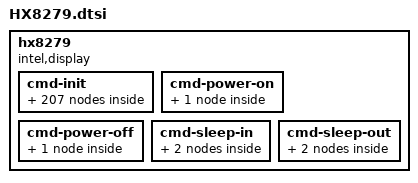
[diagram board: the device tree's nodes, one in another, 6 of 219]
	hx8279 {
		compatible = "intel,display";
		intel,display-resolution= <600 1024>;
		intel,display-dpi= <169 169>;

		/* MIPI-DSI video mode settings */
		intel,display-vid-hfp-hs-bytes = <60>;
		intel,display-vid-hbp-hs-bytes = <108>;
		intel,display-vid-hsa-hs-bytes = <72>;
		intel,display-vid-vfp-lines = <6>;
		intel,display-vid-vbp-lines = <8>;
		intel,display-vid-vsa-lines = <2>;

		intel,display-vid-mode = "pulses";
		intel,display-vid-id = <0>;
		intel,display-vid-pixel = "24packed";
		intel,display-vid-fill_buf_to = <0x1F>;

		intel,display-reset = <1 1 0 2 1 10>;

		cmd-init {
			soft-reset {
				intel,cmd-type = <0x05>;
				intel,cmd-data = <0x01>;
				intel,cmd-delay = <20>;
				intel,cmd-lp = <1>;
			};
			change-paga-number-0 {
				intel,cmd-type = <0x15>;
				intel,cmd-data = <0xB0 0x00>;
				intel,cmd-lp = <1>;
			};
			source-line {
				intel,cmd-type = <0x15>;
				intel,cmd-data = <0xBA 0xA4>;
				intel,cmd-lp = <1>;
			};
			set-vcom {
				intel,cmd-type = <0x15>;
				intel,cmd-data = <0xBD 0x71>;
				intel,cmd-lp = <1>;
			};
			set-vdd {
				intel,cmd-type = <0x15>;
				intel,cmd-data = <0xBE 0x22>;
				intel,cmd-lp = <1>;
			};
			set-vgh {
				intel,cmd-type = <0x15>;
				intel,cmd-data = <0xBF 0x19>;
				intel,cmd-lp = <1>;
			};
			set-vgl {
				intel,cmd-type = <0x15>;
				intel,cmd-data = <0xC0 0x10>;
				intel,cmd-lp = <1>;
			};
			set-pfm {
				intel,cmd-type = <0x15>;
				intel,cmd-data = <0xC1 0x78>;
				intel,cmd-lp = <1>;
			};
			set-drvp {
				intel,cmd-type = <0x15>;
				intel,cmd-data = <0xC2 0x2C>;
				intel,cmd-lp = <1>;
			};
			set-drvn {
				intel,cmd-type = <0x15>;
				intel,cmd-data = <0xC3 0x82>;
				intel,cmd-lp = <1>;
			};
			set-charge-pump {
				intel,cmd-type = <0x15>;
				intel,cmd-data = <0xC4 0x73>;
				intel,cmd-lp = <1>;
			};
			set-vgph {
				intel,cmd-type = <0x15>;
				intel,cmd-data = <0xC5 0x05>;
				intel,cmd-lp = <1>;
			};
			set-vgpl {
				intel,cmd-type = <0x15>;
				intel,cmd-data = <0xC6 0x02>;
				intel,cmd-lp = <1>;
			};
			set-vgnh {
				intel,cmd-type = <0x15>;
				intel,cmd-data = <0xC7 0x05>;
				intel,cmd-lp = <1>;
			};
			set-vgnl {
				intel,cmd-type = <0x15>;
				intel,cmd-data = <0xC8 0x03>;
				intel,cmd-lp = <1>;
			};
			set-eq0 {
				intel,cmd-type = <0x15>;
				intel,cmd-data = <0xC9 0x18>;
				intel,cmd-lp = <1>;
			};
			set-page-number-1 {
				intel,cmd-type = <0x15>;
				intel,cmd-data = <0xB0 0x01>;
				intel,cmd-lp = <1>;
			};
			pgamma-0 {
				intel,cmd-type = <0x15>;
				intel,cmd-data = <0xB1 0x00>;
				intel,cmd-lp = <1>;
			};
			pgamma-1 {
				intel,cmd-type = <0x15>;
				intel,cmd-data = <0xB2 0x2C>;
				intel,cmd-lp = <1>;
			};
			pgamma-2 {
				intel,cmd-type = <0x15>;
				intel,cmd-data = <0xB3 0x5C>;
				intel,cmd-lp = <1>;
			};
			pgamma-3 {
				intel,cmd-type = <0x15>;
				intel,cmd-data = <0xB4 0xAC>;
				intel,cmd-lp = <1>;
			};
			pgamma-4 {
				intel,cmd-type = <0x15>;
				intel,cmd-data = <0xB5 0xDC>;
				intel,cmd-lp = <1>;
			};
			pgamma-5 {
				intel,cmd-type = <0x15>;
				intel,cmd-data = <0xB6 0x5C>;
				intel,cmd-lp = <1>;
			};
			pgamma-6 {
				intel,cmd-type = <0x15>;
				intel,cmd-data = <0xB7 0x9C>;
				intel,cmd-lp = <1>;
			};
			pgamma-7 {
				intel,cmd-type = <0x15>;
				intel,cmd-data = <0xB8 0xCC>;
				intel,cmd-lp = <1>;
			};
			pgamma-8 {
				intel,cmd-type = <0x15>;
				intel,cmd-data = <0xB9 0x0C>;
				intel,cmd-lp = <1>;
			};
			pgamma-9 {
				intel,cmd-type = <0x15>;
				intel,cmd-data = <0xBA 0x3C>;
				intel,cmd-lp = <1>;
			};
			pgamma-10 {
				intel,cmd-type = <0x15>;
				intel,cmd-data = <0xBB 0x6C>;
				intel,cmd-lp = <1>;
			};
			pgamma-11 {
				intel,cmd-type = <0x15>;
				intel,cmd-data = <0xBC 0x9C>;
				intel,cmd-lp = <1>;
			};
			pgamma-12 {
				intel,cmd-type = <0x15>;
				intel,cmd-data = <0xBD 0xCC>;
				intel,cmd-lp = <1>;
			};
			pgamma-13 {
				intel,cmd-type = <0x15>;
				intel,cmd-data = <0xBE 0xFC>;
				intel,cmd-lp = <1>;
			};
			pgamma-14 {
				intel,cmd-type = <0x15>;
				intel,cmd-data = <0xBF 0x2C>;
				intel,cmd-lp = <1>;
			};
			pgamma-15 {
				intel,cmd-type = <0x15>;
				intel,cmd-data = <0xC0 0x5C>;
				intel,cmd-lp = <1>;
			};
			pgamma-16 {
				intel,cmd-type = <0x15>;
				intel,cmd-data = <0xC1 0xFC>;
				intel,cmd-lp = <1>;
			};
			pgamma-17 {
				intel,cmd-type = <0x15>;
				intel,cmd-data = <0xC2 0x00>;
				intel,cmd-lp = <1>;
			};
			pgamma-18 {
				intel,cmd-type = <0x15>;
				intel,cmd-data = <0xC3 0x15>;
				intel,cmd-lp = <1>;
			};
			pgamma-19 {
				intel,cmd-type = <0x15>;
				intel,cmd-data = <0xC4 0xAA>;
				intel,cmd-lp = <1>;
			};
			pgamma-20 {
				intel,cmd-type = <0x15>;
				intel,cmd-data = <0xC5 0xAF>;
				intel,cmd-lp = <1>;
			};
			pgamma-21 {
				intel,cmd-type = <0x15>;
				intel,cmd-data = <0xC6 0x03>;
				intel,cmd-lp = <1>;
			};
			pgamma-22 {
				intel,cmd-type = <0x15>;
				intel,cmd-data = <0xC7 0x00>;
				intel,cmd-lp = <1>;
			};
			pgamma-23 {
				intel,cmd-type = <0x15>;
				intel,cmd-data = <0xC8 0x2C>;
				intel,cmd-lp = <1>;
			};
			pgamma-24 {
				intel,cmd-type = <0x15>;
				intel,cmd-data = <0xC9 0x5C>;
				intel,cmd-lp = <1>;
			};
			pgamma-25 {
				intel,cmd-type = <0x15>;
				intel,cmd-data = <0xCA 0xAC>;
				intel,cmd-lp = <1>;
			};
			pgamma-26 {
				intel,cmd-type = <0x15>;
				intel,cmd-data = <0xCB 0xDC>;
				intel,cmd-lp = <1>;
			};
			pgamma-27 {
				intel,cmd-type = <0x15>;
				intel,cmd-data = <0xCC 0x5C>;
				intel,cmd-lp = <1>;
			};
			pgamma-28 {
				intel,cmd-type = <0x15>;
				intel,cmd-data = <0xCD 0x9C>;
				intel,cmd-lp = <1>;
			};
			pgamma-29 {
				intel,cmd-type = <0x15>;
				intel,cmd-data = <0xCE 0xCC>;
				intel,cmd-lp = <1>;
			};
			pgamma-30 {
				intel,cmd-type = <0x15>;
				intel,cmd-data = <0xCF 0x0C>;
				intel,cmd-lp = <1>;
			};
			pgamma-31 {
				intel,cmd-type = <0x15>;
				intel,cmd-data = <0xD0 0x3C>;
				intel,cmd-lp = <1>;
			};
			pgamma-32 {
				intel,cmd-type = <0x15>;
				intel,cmd-data = <0xD1 0x6C>;
				intel,cmd-lp = <1>;
			};
			pgamma-33 {
				intel,cmd-type = <0x15>;
				intel,cmd-data = <0xD2 0x9C>;
				intel,cmd-lp = <1>;
			};
			pgamma-34 {
				intel,cmd-type = <0x15>;
				intel,cmd-data = <0xD3 0xCC>;
				intel,cmd-lp = <1>;
			};
			pgamma-35 {
				intel,cmd-type = <0x15>;
				intel,cmd-data = <0xD4 0xFC>;
				intel,cmd-lp = <1>;
			};
			pgamma-36 {
				intel,cmd-type = <0x15>;
				intel,cmd-data = <0xD5 0x2C>;
				intel,cmd-lp = <1>;
			};
			pgamma-37 {
				intel,cmd-type = <0x15>;
				intel,cmd-data = <0xD6 0x5C>;
				intel,cmd-lp = <1>;
			};
			pgamma-38 {
				intel,cmd-type = <0x15>;
				intel,cmd-data = <0xD7 0xFC>;
				intel,cmd-lp = <1>;
			};
			pgamma-39 {
				intel,cmd-type = <0x15>;
				intel,cmd-data = <0xD8 0x00>;
				intel,cmd-lp = <1>;
			};
			pgamma-40 {
				intel,cmd-type = <0x15>;
				intel,cmd-data = <0xD9 0x15>;
				intel,cmd-lp = <1>;
			};
			pgamma-41 {
				intel,cmd-type = <0x15>;
				intel,cmd-data = <0xDA 0xAA>;
				intel,cmd-lp = <1>;
			};
			pgamma-42 {
				intel,cmd-type = <0x15>;
				intel,cmd-data = <0xDB 0xAF>;
				intel,cmd-lp = <1>;
			};
			pgamma-43 {
				intel,cmd-type = <0x15>;
				intel,cmd-data = <0xDC 0x03>;
				intel,cmd-lp = <1>;
			};
			pgamma-44 {
				intel,cmd-type = <0x15>;
				intel,cmd-data = <0xDD 0x00>;
				intel,cmd-lp = <1>;
			};
			pgamma-45 {
				intel,cmd-type = <0x15>;
				intel,cmd-data = <0xDE 0x2C>;
				intel,cmd-lp = <1>;
			};
			pgamma-46 {
				intel,cmd-type = <0x15>;
				intel,cmd-data = <0xDF 0x5C>;
				intel,cmd-lp = <1>;
			};
			pgamma-47 {
				intel,cmd-type = <0x15>;
				intel,cmd-data = <0xE0 0xAC>;
				intel,cmd-lp = <1>;
			};
			pgamma-48 {
				intel,cmd-type = <0x15>;
				intel,cmd-data = <0xE1 0xDC>;
				intel,cmd-lp = <1>;
			};
			pgamma-49 {
				intel,cmd-type = <0x15>;
				intel,cmd-data = <0xE2 0x5C>;
				intel,cmd-lp = <1>;
			};
			pgamma-50 {
				intel,cmd-type = <0x15>;
				intel,cmd-data = <0xE3 0x9C>;
				intel,cmd-lp = <1>;
			};
			pgamma-51 {
				intel,cmd-type = <0x15>;
				intel,cmd-data = <0xE4 0xCC>;
				intel,cmd-lp = <1>;
			};
			pgamma-52 {
				intel,cmd-type = <0x15>;
				intel,cmd-data = <0xE5 0x0C>;
				intel,cmd-lp = <1>;
			};
			pgamma-53 {
				intel,cmd-type = <0x15>;
				intel,cmd-data = <0xE6 0x3C>;
				intel,cmd-lp = <1>;
			};
			pgamma-54 {
				intel,cmd-type = <0x15>;
				intel,cmd-data = <0xE7 0x6C>;
				intel,cmd-lp = <1>;
			};
			pgamma-55 {
				intel,cmd-type = <0x15>;
				intel,cmd-data = <0xE8 0x9C>;
				intel,cmd-lp = <1>;
			};
			pgamma-56 {
				intel,cmd-type = <0x15>;
				intel,cmd-data = <0xE9 0xCC>;
				intel,cmd-lp = <1>;
			};
			pgamma-57 {
				intel,cmd-type = <0x15>;
				intel,cmd-data = <0xEA 0xFC>;
				intel,cmd-lp = <1>;
			};
			pgamma-58 {
				intel,cmd-type = <0x15>;
				intel,cmd-data = <0xEB 0x2C>;
				intel,cmd-lp = <1>;
			};
			pgamma-59 {
				intel,cmd-type = <0x15>;
				intel,cmd-data = <0xEC 0x5C>;
				intel,cmd-lp = <1>;
			};
			pgamma-60 {
				intel,cmd-type = <0x15>;
				intel,cmd-data = <0xED 0xFC>;
				intel,cmd-lp = <1>;
			};
			pgamma-61 {
				intel,cmd-type = <0x15>;
				intel,cmd-data = <0xEE 0x00>;
				intel,cmd-lp = <1>;
			};
			pgamma-62 {
				intel,cmd-type = <0x15>;
				intel,cmd-data = <0xEF 0x15>;
				intel,cmd-lp = <1>;
			};
			pgamma-63 {
				intel,cmd-type = <0x15>;
				intel,cmd-data = <0xF0 0xAA>;
				intel,cmd-lp = <1>;
			};
			pgamma-64 {
				intel,cmd-type = <0x15>;
				intel,cmd-data = <0xF1 0xAF>;
				intel,cmd-lp = <1>;
			};
			pgamma-65 {
				intel,cmd-type = <0x15>;
				intel,cmd-data = <0xF2 0x03>;
				intel,cmd-lp = <1>;
			};
			set-page-number-2 {
				intel,cmd-type = <0x15>;
				intel,cmd-data = <0xB0 0x02>;
				intel,cmd-lp = <1>;
			};
			ngamma-0 {
				intel,cmd-type = <0x15>;
				intel,cmd-data = <0xB1 0x00>;
				intel,cmd-lp = <1>;
			};
			ngamma-1 {
				intel,cmd-type = <0x15>;
				intel,cmd-data = <0xB2 0x2C>;
				intel,cmd-lp = <1>;
			};
			ngamma-2 {
				intel,cmd-type = <0x15>;
				intel,cmd-data = <0xB3 0x5C>;
				intel,cmd-lp = <1>;
			};
			ngamma-3 {
				intel,cmd-type = <0x15>;
				intel,cmd-data = <0xB4 0xAC>;
				intel,cmd-lp = <1>;
			};
			ngamma-4 {
				intel,cmd-type = <0x15>;
				intel,cmd-data = <0xB5 0xDC>;
				intel,cmd-lp = <1>;
			};
			ngamma-5 {
				intel,cmd-type = <0x15>;
				intel,cmd-data = <0xB6 0x5C>;
				intel,cmd-lp = <1>;
			};
			ngamma-6 {
				intel,cmd-type = <0x15>;
				intel,cmd-data = <0xB7 0x9C>;
				intel,cmd-lp = <1>;
			};
			ngamma-7 {
				intel,cmd-type = <0x15>;
				intel,cmd-data = <0xB8 0xCC>;
				intel,cmd-lp = <1>;
			};
			ngamma-8 {
				intel,cmd-type = <0x15>;
				intel,cmd-data = <0xB9 0x0C>;
				intel,cmd-lp = <1>;
			};
			ngamma-9 {
				intel,cmd-type = <0x15>;
				intel,cmd-data = <0xBA 0x3C>;
				intel,cmd-lp = <1>;
			};
			ngamma-10 {
				intel,cmd-type = <0x15>;
				intel,cmd-data = <0xBB 0x6C>;
				intel,cmd-lp = <1>;
			};
			ngamma-11 {
				intel,cmd-type = <0x15>;
				intel,cmd-data = <0xBC 0x9C>;
				intel,cmd-lp = <1>;
			};
			ngamma-12 {
				intel,cmd-type = <0x15>;
				intel,cmd-data = <0xBD 0xCC>;
				intel,cmd-lp = <1>;
			};
			ngamma-13 {
				intel,cmd-type = <0x15>;
				intel,cmd-data = <0xBE 0xFC>;
				intel,cmd-lp = <1>;
			};
			ngamma-14 {
				intel,cmd-type = <0x15>;
				intel,cmd-data = <0xBF 0x2C>;
				intel,cmd-lp = <1>;
			};
			ngamma-15 {
				intel,cmd-type = <0x15>;
				intel,cmd-data = <0xC0 0x5C>;
				intel,cmd-lp = <1>;
			};
			ngamma-16 {
				intel,cmd-type = <0x15>;
				intel,cmd-data = <0xC1 0xFC>;
				intel,cmd-lp = <1>;
			};
			ngamma-17 {
				intel,cmd-type = <0x15>;
				intel,cmd-data = <0xC2 0x00>;
				intel,cmd-lp = <1>;
			};
			ngamma-18 {
				intel,cmd-type = <0x15>;
				intel,cmd-data = <0xC3 0x15>;
				intel,cmd-lp = <1>;
			};
			ngamma-19 {
				intel,cmd-type = <0x15>;
				intel,cmd-data = <0xC4 0xAA>;
				intel,cmd-lp = <1>;
			};
			ngamma-20 {
				intel,cmd-type = <0x15>;
				intel,cmd-data = <0xC5 0xAF>;
				intel,cmd-lp = <1>;
			};
			ngamma-21 {
				intel,cmd-type = <0x15>;
				intel,cmd-data = <0xC6 0x03>;
				intel,cmd-lp = <1>;
			};
			ngamma-22 {
				intel,cmd-type = <0x15>;
				intel,cmd-data = <0xC7 0x00>;
				intel,cmd-lp = <1>;
			};
			ngamma-23 {
				intel,cmd-type = <0x15>;
				intel,cmd-data = <0xC8 0x2C>;
				intel,cmd-lp = <1>;
			};
			ngamma-24 {
				intel,cmd-type = <0x15>;
				intel,cmd-data = <0xC9 0x5C>;
				intel,cmd-lp = <1>;
			};
			ngamma-25 {
				intel,cmd-type = <0x15>;
				intel,cmd-data = <0xCA 0xAC>;
				intel,cmd-lp = <1>;
			};
			ngamma-26 {
				intel,cmd-type = <0x15>;
				intel,cmd-data = <0xCB 0xDC>;
				intel,cmd-lp = <1>;
			};
			ngamma-27 {
				intel,cmd-type = <0x15>;
				intel,cmd-data = <0xCC 0x5C>;
				intel,cmd-lp = <1>;
			};
			ngamma-28 {
				intel,cmd-type = <0x15>;
				intel,cmd-data = <0xCD 0x9C>;
				intel,cmd-lp = <1>;
			};
			ngamma-29 {
				intel,cmd-type = <0x15>;
				intel,cmd-data = <0xCE 0xCC>;
				intel,cmd-lp = <1>;
			};
			ngamma-30 {
				intel,cmd-type = <0x15>;
				intel,cmd-data = <0xCF 0x0C>;
				intel,cmd-lp = <1>;
			};
			ngamma-31 {
				intel,cmd-type = <0x15>;
				intel,cmd-data = <0xD0 0x3C>;
				intel,cmd-lp = <1>;
			};
			ngamma-32 {
				intel,cmd-type = <0x15>;
				intel,cmd-data = <0xD1 0x6C>;
				intel,cmd-lp = <1>;
			};
			ngamma-33 {
				intel,cmd-type = <0x15>;
				intel,cmd-data = <0xD2 0x9C>;
				intel,cmd-lp = <1>;
			};
			ngamma-34 {
				intel,cmd-type = <0x15>;
				intel,cmd-data = <0xD3 0xCC>;
				intel,cmd-lp = <1>;
			};
			ngamma-35 {
				intel,cmd-type = <0x15>;
				intel,cmd-data = <0xD4 0xFC>;
				intel,cmd-lp = <1>;
			};
			ngamma-36 {
				intel,cmd-type = <0x15>;
				intel,cmd-data = <0xD5 0x2C>;
				intel,cmd-lp = <1>;
			};
			ngamma-37 {
				intel,cmd-type = <0x15>;
				intel,cmd-data = <0xD6 0x5C>;
				intel,cmd-lp = <1>;
			};
			ngamma-38 {
				intel,cmd-type = <0x15>;
				intel,cmd-data = <0xD7 0xFC>;
				intel,cmd-lp = <1>;
			};
			ngamma-39 {
				intel,cmd-type = <0x15>;
				intel,cmd-data = <0xD8 0x00>;
				intel,cmd-lp = <1>;
			};
			ngamma-40 {
				intel,cmd-type = <0x15>;
				intel,cmd-data = <0xD9 0x15>;
				intel,cmd-lp = <1>;
			};
			ngamma-41 {
				intel,cmd-type = <0x15>;
				intel,cmd-data = <0xDA 0xAA>;
				intel,cmd-lp = <1>;
			};
			ngamma-42 {
				intel,cmd-type = <0x15>;
				intel,cmd-data = <0xDB 0xAF>;
				intel,cmd-lp = <1>;
			};
			ngamma-43 {
				intel,cmd-type = <0x15>;
				intel,cmd-data = <0xDC 0x03>;
				intel,cmd-lp = <1>;
			};
			ngamma-44 {
				intel,cmd-type = <0x15>;
				intel,cmd-data = <0xDD 0x00>;
				intel,cmd-lp = <1>;
			};
			ngamma-45 {
				intel,cmd-type = <0x15>;
				intel,cmd-data = <0xDE 0x2C>;
				intel,cmd-lp = <1>;
			};
			ngamma-46 {
				intel,cmd-type = <0x15>;
				intel,cmd-data = <0xDF 0x5C>;
				intel,cmd-lp = <1>;
			};
			ngamma-47 {
				intel,cmd-type = <0x15>;
				intel,cmd-data = <0xE0 0xAC>;
				intel,cmd-lp = <1>;
			};
			ngamma-48 {
				intel,cmd-type = <0x15>;
				intel,cmd-data = <0xE1 0xDC>;
				intel,cmd-lp = <1>;
			};
			ngamma-49 {
				intel,cmd-type = <0x15>;
				intel,cmd-data = <0xE2 0x5C>;
				intel,cmd-lp = <1>;
			};
			ngamma-50 {
				intel,cmd-type = <0x15>;
				intel,cmd-data = <0xE3 0x9C>;
				intel,cmd-lp = <1>;
			};
			ngamma-51 {
				intel,cmd-type = <0x15>;
				intel,cmd-data = <0xE4 0xCC>;
				intel,cmd-lp = <1>;
			};
			ngamma-52 {
				intel,cmd-type = <0x15>;
				intel,cmd-data = <0xE5 0x0C>;
				intel,cmd-lp = <1>;
			};
			ngamma-53 {
				intel,cmd-type = <0x15>;
				intel,cmd-data = <0xE6 0x3C>;
				intel,cmd-lp = <1>;
			};
			ngamma-54 {
				intel,cmd-type = <0x15>;
				intel,cmd-data = <0xE7 0x6C>;
				intel,cmd-lp = <1>;
			};
			ngamma-55 {
				intel,cmd-type = <0x15>;
				intel,cmd-data = <0xE8 0x9C>;
				intel,cmd-lp = <1>;
			};
			ngamma-56 {
				intel,cmd-type = <0x15>;
				intel,cmd-data = <0xE9 0xCC>;
				intel,cmd-lp = <1>;
			};
			ngamma-57 {
				intel,cmd-type = <0x15>;
				intel,cmd-data = <0xEA 0xFC>;
				intel,cmd-lp = <1>;
			};
			ngamma-58 {
				intel,cmd-type = <0x15>;
				intel,cmd-data = <0xEB 0x2C>;
				intel,cmd-lp = <1>;
			};
			ngamma-59 {
				intel,cmd-type = <0x15>;
				intel,cmd-data = <0xEC 0x5C>;
				intel,cmd-lp = <1>;
			};
			ngamma-60 {
				intel,cmd-type = <0x15>;
				intel,cmd-data = <0xED 0xFC>;
				intel,cmd-lp = <1>;
			};
			ngamma-61 {
				intel,cmd-type = <0x15>;
				intel,cmd-data = <0xEE 0x00>;
				intel,cmd-lp = <1>;
			};
			ngamma-62 {
				intel,cmd-type = <0x15>;
				intel,cmd-data = <0xEF 0x15>;
				intel,cmd-lp = <1>;
			};
			ngamma-63 {
				intel,cmd-type = <0x15>;
				intel,cmd-data = <0xF0 0xAA>;
				intel,cmd-lp = <1>;
			};
			ngamma-64 {
				intel,cmd-type = <0x15>;
				intel,cmd-data = <0xF1 0xAF>;
				intel,cmd-lp = <1>;
			};
			ngamma-65 {
				intel,cmd-type = <0x15>;
				intel,cmd-data = <0xF2 0x03>;
				intel,cmd-lp = <1>;
			};
			set-page-number-3 {
				intel,cmd-type = <0x15>;
				intel,cmd-data = <0xB0 0x03>;
				intel,cmd-lp = <1>;
			};
			set-goa-0 {
				intel,cmd-type = <0x15>;
				intel,cmd-data = <0xC0 0x40>;
				intel,cmd-lp = <1>;
			};
			set-goa-1 {
				intel,cmd-type = <0x15>;
				intel,cmd-data = <0xC1 0x10>;
				intel,cmd-lp = <1>;
			};
			set-goa-2 {
				intel,cmd-type = <0x15>;
				intel,cmd-data = <0xC4 0x2F>;
				intel,cmd-lp = <1>;
			};
			set-goa-3 {
				intel,cmd-type = <0x15>;
				intel,cmd-data = <0xC5 0x9E>;
				intel,cmd-lp = <1>;
			};
			set-goa-4 {
				intel,cmd-type = <0x15>;
				intel,cmd-data = <0xC8 0x41>;
				intel,cmd-lp = <1>;
			};
			set-goa-5 {
				intel,cmd-type = <0x15>;
				intel,cmd-data = <0xC9 0x61>;
				intel,cmd-lp = <1>;
			};
			set-goa-6 {
				intel,cmd-type = <0x15>;
				intel,cmd-data = <0xCA 0x01>;
				intel,cmd-lp = <1>;
			};
			set-goa-7 {
				intel,cmd-type = <0x15>;
				intel,cmd-data = <0xCB 0x00>;
				intel,cmd-lp = <1>;
			};
			set-gout-0 {
				intel,cmd-type = <0x15>;
				intel,cmd-data = <0xDC 0x01>;
				intel,cmd-lp = <1>;
			};
			set-gout-1 {
				intel,cmd-type = <0x15>;
				intel,cmd-data = <0xDD 0x07>;
				intel,cmd-lp = <1>;
			};
			set-gout-2 {
				intel,cmd-type = <0x15>;
				intel,cmd-data = <0xDE 0x05>;
				intel,cmd-lp = <1>;
			};
			set-gout-3 {
				intel,cmd-type = <0x15>;
				intel,cmd-data = <0xDF 0x00>;
				intel,cmd-lp = <1>;
			};
			set-gout-4 {
				intel,cmd-type = <0x15>;
				intel,cmd-data = <0xE0 0x00>;
				intel,cmd-lp = <1>;
			};
			set-gout-5 {
				intel,cmd-type = <0x15>;
				intel,cmd-data = <0xE1 0x00>;
				intel,cmd-lp = <1>;
			};
			set-gout-6 {
				intel,cmd-type = <0x15>;
				intel,cmd-data = <0xE2 0x00>;
				intel,cmd-lp = <1>;
			};
			set-gout-7 {
				intel,cmd-type = <0x15>;
				intel,cmd-data = <0xE3 0x00>;
				intel,cmd-lp = <1>;
			};
			set-gout-8 {
				intel,cmd-type = <0x15>;
				intel,cmd-data = <0xE4 0x00>;
				intel,cmd-lp = <1>;
			};
			set-gout-9 {
				intel,cmd-type = <0x15>;
				intel,cmd-data = <0xE5 0x00>;
				intel,cmd-lp = <1>;
			};
			set-gout-10 {
				intel,cmd-type = <0x15>;
				intel,cmd-data = <0xE6 0x00>;
				intel,cmd-lp = <1>;
			};
			set-gout-11 {
				intel,cmd-type = <0x15>;
				intel,cmd-data = <0xE7 0x00>;
				intel,cmd-lp = <1>;
			};
			set-gout-12 {
				intel,cmd-type = <0x15>;
				intel,cmd-data = <0xE8 0x00>;
				intel,cmd-lp = <1>;
			};
			set-gout-13 {
				intel,cmd-type = <0x15>;
				intel,cmd-data = <0xE9 0x00>;
				intel,cmd-lp = <1>;
			};
			set-gout-14 {
				intel,cmd-type = <0x15>;
				intel,cmd-data = <0xEA 0x00>;
				intel,cmd-lp = <1>;
			};
			set-gout-15 {
				intel,cmd-type = <0x15>;
				intel,cmd-data = <0xEB 0x00>;
				intel,cmd-lp = <1>;
			};
			set-gout-16 {
				intel,cmd-type = <0x15>;
				intel,cmd-data = <0xEC 0x02>;
				intel,cmd-lp = <1>;
			};
			set-gout-17 {
				intel,cmd-type = <0x15>;
				intel,cmd-data = <0xED 0x08>;
				intel,cmd-lp = <1>;
			};
			set-gout-18 {
				intel,cmd-type = <0x15>;
				intel,cmd-data = <0xEE 0x06>;
				intel,cmd-lp = <1>;
			};
			set-gout-19 {
				intel,cmd-type = <0x15>;
				intel,cmd-data = <0xEF 0x00>;
				intel,cmd-lp = <1>;
			};
			set-gout-20 {
				intel,cmd-type = <0x15>;
				intel,cmd-data = <0xF0 0x00>;
				intel,cmd-lp = <1>;
			};
			set-gout-21 {
				intel,cmd-type = <0x15>;
				intel,cmd-data = <0xF1 0x00>;
				intel,cmd-lp = <1>;
			};
			set-gout-22 {
				intel,cmd-type = <0x15>;
				intel,cmd-data = <0xF2 0x00>;
				intel,cmd-lp = <1>;
			};
			set-gout-23 {
				intel,cmd-type = <0x15>;
				intel,cmd-data = <0xF3 0x00>;
				intel,cmd-lp = <1>;
			};
			set-gout-24 {
				intel,cmd-type = <0x15>;
				intel,cmd-data = <0xF4 0x00>;
				intel,cmd-lp = <1>;
			};
			set-gout-25 {
				intel,cmd-type = <0x15>;
				intel,cmd-data = <0xF5 0x00>;
				intel,cmd-lp = <1>;
			};
			set-gout-26 {
				intel,cmd-type = <0x15>;
				intel,cmd-data = <0xF6 0x00>;
				intel,cmd-lp = <1>;
			};
			set-gout-27 {
				intel,cmd-type = <0x15>;
				intel,cmd-data = <0xF7 0x00>;
				intel,cmd-lp = <1>;
			};
			set-gout-28 {
				intel,cmd-type = <0x15>;
				intel,cmd-data = <0xF8 0x00>;
				intel,cmd-lp = <1>;
			};
			set-gout-29 {
				intel,cmd-type = <0x15>;
				intel,cmd-data = <0xF9 0x00>;
				intel,cmd-lp = <1>;
			};
			set-gout-30 {
				intel,cmd-type = <0x15>;
				intel,cmd-data = <0xFA 0x00>;
				intel,cmd-lp = <1>;
			};
			set-gout-31 {
				intel,cmd-type = <0x15>;
				intel,cmd-data = <0xFB 0x00>;
				intel,cmd-lp = <1>;
			};
			set-page-number-5 {
				intel,cmd-type = <0x15>;
				intel,cmd-data = <0xB0 0x05>;
				intel,cmd-lp = <1>;
			};
			set-hs-prepare-time {
				intel,cmd-type = <0x15>;
				intel,cmd-data = <0xB3 0x52>;
				intel,cmd-lp = <1>;
			};
			set-page-number-6 {
				intel,cmd-type = <0x15>;
				intel,cmd-data = <0xB0 0x06>;
				intel,cmd-lp = <1>;
			};
			set-function-password-1 {
				intel,cmd-type = <0x15>;
				intel,cmd-data = <0xB8 0xA5>;
				intel,cmd-lp = <1>;
			};
			set-function-password-2 {
				intel,cmd-type = <0x15>;
				intel,cmd-data = <0xC0 0xA5>;
				intel,cmd-lp = <1>;
			};
			set-vddd {
				intel,cmd-type = <0x15>;
				intel,cmd-data = <0xC7 0x1F>;
				intel,cmd-lp = <1>;
			};
			set-eq0-on {
				intel,cmd-type = <0x15>;
				intel,cmd-data = <0xCE 0x4F>;
				intel,cmd-lp = <1>;
			};
			disable-function-set-1 {
				intel,cmd-type = <0x15>;
				intel,cmd-data = <0xB8 0x5A>;
				intel,cmd-lp = <1>;
			};
			disable-function-set-2 {
				intel,cmd-type = <0x15>;
				intel,cmd-data = <0xC0 0x5A>;
				intel,cmd-lp = <1>;
			};
			set-page-number-3-1 {
				intel,cmd-type = <0x15>;
				intel,cmd-data = <0xB0 0x03>;
				intel,cmd-lp = <1>;
			};
			reload-otp-1 {
				intel,cmd-type = <0x15>;
				intel,cmd-data = <0xB2 0xA5>;
				intel,cmd-lp = <1>;
			};
			reload-otp-2 {
				intel,cmd-type = <0x15>;
				intel,cmd-data = <0xB3 0x04>;
				intel,cmd-lp = <1>;
			};
			set-page-number-end {
				intel,cmd-type = <0x15>;
				intel,cmd-data = <0xB0 0x0F>;
				intel,cmd-lp = <1>;
			};
			set-address-mode {
				intel,cmd-type = <0x15>;
				intel,cmd-data = <0x36 0x08>;
				intel,cmd-lp = <1>;
			};
			sleep-out {
				intel,cmd-type = <0x05>;
				intel,cmd-data = <0x11>;
				intel,cmd-delay = <200>;
				intel,cmd-lp = <1>;
			};
			display-on {
				intel,cmd-type = <0x05>;
				intel,cmd-data = <0x29>;
				intel,cmd-lp = <1>;
			};
		};

		cmd-power-on {
			display-on {
				intel,cmd-type = <0x05>;
				intel,cmd-data = <0x29>;
				intel,cmd-lp = <1>;
			};
		};

		cmd-power-off {
			display-off {
				intel,cmd-type = <0x05>;
				intel,cmd-data = <0x28>;
				intel,cmd-lp = <1>;
			};
		};

		cmd-sleep-in {
			display-off {
				intel,cmd-type = <0x05>;
				intel,cmd-data = <0x28>;
				intel,cmd-lp = <1>;
			};
			sleep-in {
				intel,cmd-type = <0x05>;
				intel,cmd-data = <0x10>;
				intel,cmd-delay = <200>;
				intel,cmd-lp = <1>;
			};
		};

		cmd-sleep-out {
			sleep-out {
				intel,cmd-type = <0x05>;
				intel,cmd-data = <0x11>;
				intel,cmd-delay = <200>;
				intel,cmd-lp = <1>;
			};
			display-on {
				intel,cmd-type = <0x05>;
				intel,cmd-data = <0x29>;
				intel,cmd-lp = <1>;
			};
		};

	};
